# ESP32-C5 register map
Vendor: ESPRESSIF SYSTEMS (SHANGHAI) CO., LTD.; Series: ESP32 C-Series; File version: 1
CPU: RV32IMAC r0p0, little endian, no MPU, no FPU, 0 interrupt priority bits
Address unit: 32 bits
Registers are 32-bit, read-write, reset 0x0 unless marked. A register's access mark holds for its fields unless they carry their own. Offsets are from the block's base; [hi:lo] are bit positions; {n}, {i} and the like mark numbered series.

## SOC_ETM (part 2 of 2) — Event Task Matrix
Base 0x60013000
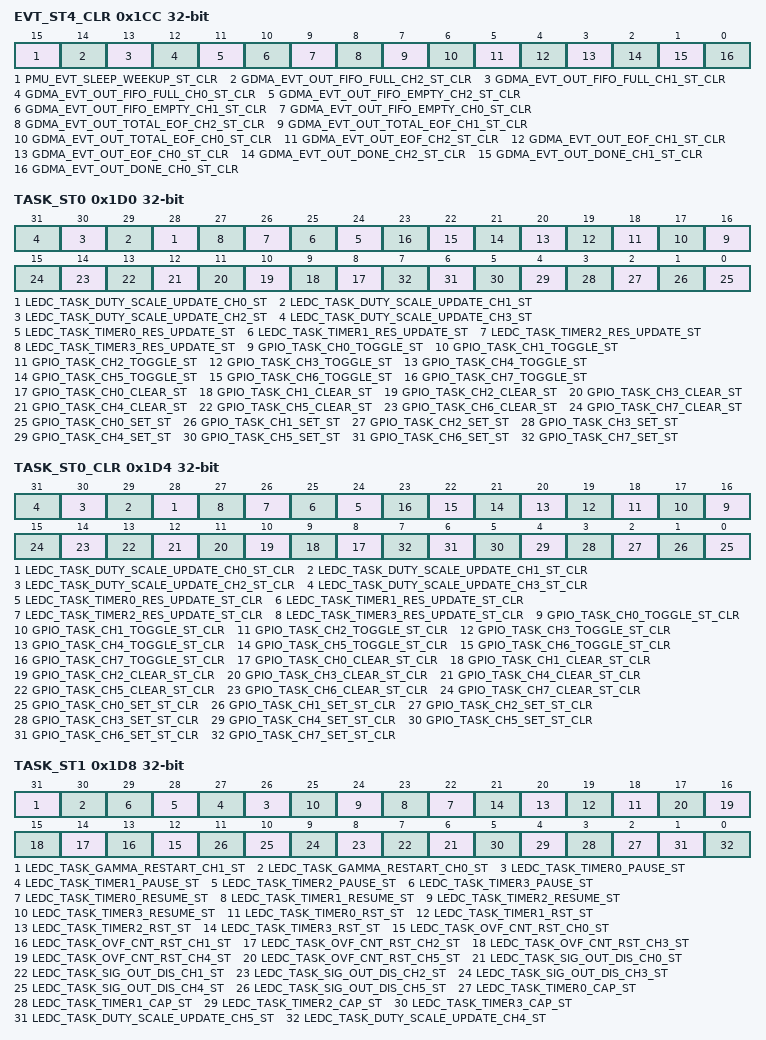
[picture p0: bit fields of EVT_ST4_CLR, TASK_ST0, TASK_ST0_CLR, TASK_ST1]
0x1CC EVT_ST4_CLR wo — Events trigger status clear register
  [15] PMU_EVT_SLEEP_WEEKUP_ST_CLR — Configures whether or not to clear PMU_evt_sleep_weekup trigger status.\\0: Invalid, No effect\\1: Clear
  [14] GDMA_EVT_OUT_FIFO_FULL_CH2_ST_CLR — Configures whether or not to clear GDMA_evt_out_fifo_full_ch2 trigger status.\\0: Invalid, No effect\\1: Clear
  [13] GDMA_EVT_OUT_FIFO_FULL_CH1_ST_CLR — Configures whether or not to clear GDMA_evt_out_fifo_full_ch1 trigger status.\\0: Invalid, No effect\\1: Clear
  [12] GDMA_EVT_OUT_FIFO_FULL_CH0_ST_CLR — Configures whether or not to clear GDMA_evt_out_fifo_full_ch0 trigger status.\\0: Invalid, No effect\\1: Clear
  [11] GDMA_EVT_OUT_FIFO_EMPTY_CH2_ST_CLR — Configures whether or not to clear GDMA_evt_out_fifo_empty_ch2 trigger status.\\0: Invalid, No effect\\1: Clear
  [10] GDMA_EVT_OUT_FIFO_EMPTY_CH1_ST_CLR — Configures whether or not to clear GDMA_evt_out_fifo_empty_ch1 trigger status.\\0: Invalid, No effect\\1: Clear
  [9] GDMA_EVT_OUT_FIFO_EMPTY_CH0_ST_CLR — Configures whether or not to clear GDMA_evt_out_fifo_empty_ch0 trigger status.\\0: Invalid, No effect\\1: Clear
  [8] GDMA_EVT_OUT_TOTAL_EOF_CH2_ST_CLR — Configures whether or not to clear GDMA_evt_out_total_eof_ch2 trigger status.\\0: Invalid, No effect\\1: Clear
  [7] GDMA_EVT_OUT_TOTAL_EOF_CH1_ST_CLR — Configures whether or not to clear GDMA_evt_out_total_eof_ch1 trigger status.\\0: Invalid, No effect\\1: Clear
  [6] GDMA_EVT_OUT_TOTAL_EOF_CH0_ST_CLR — Configures whether or not to clear GDMA_evt_out_total_eof_ch0 trigger status.\\0: Invalid, No effect\\1: Clear
  [5] GDMA_EVT_OUT_EOF_CH2_ST_CLR — Configures whether or not to clear GDMA_evt_out_eof_ch2 trigger status.\\0: Invalid, No effect\\1: Clear
  [4] GDMA_EVT_OUT_EOF_CH1_ST_CLR — Configures whether or not to clear GDMA_evt_out_eof_ch1 trigger status.\\0: Invalid, No effect\\1: Clear
  [3] GDMA_EVT_OUT_EOF_CH0_ST_CLR — Configures whether or not to clear GDMA_evt_out_eof_ch0 trigger status.\\0: Invalid, No effect\\1: Clear
  [2] GDMA_EVT_OUT_DONE_CH2_ST_CLR — Configures whether or not to clear GDMA_evt_out_done_ch2 trigger status.\\0: Invalid, No effect\\1: Clear
  [1] GDMA_EVT_OUT_DONE_CH1_ST_CLR — Configures whether or not to clear GDMA_evt_out_done_ch1 trigger status.\\0: Invalid, No effect\\1: Clear
  [0] GDMA_EVT_OUT_DONE_CH0_ST_CLR — Configures whether or not to clear GDMA_evt_out_done_ch0 trigger status.\\0: Invalid, No effect\\1: Clear
0x1D0 TASK_ST0 — Tasks trigger status register
  [n+28] LEDC_TASK_DUTY_SCALE_UPDATE_CH{n}_ST (n=0..3) — Represents LEDC_task_duty_scale_update_ch{n} trigger status.\\0: Not triggered\\1: Triggered
  [n+24] LEDC_TASK_TIMER{n}_RES_UPDATE_ST (n=0..3) — Represents LEDC_task_timer{n}_res_update trigger status.\\0: Not triggered\\1: Triggered
  [n+16] GPIO_TASK_CH{n}_TOGGLE_ST (n=0..7) — Represents GPIO_task_ch{n}_toggle trigger status.\\0: Not triggered\\1: Triggered
  [n+8] GPIO_TASK_CH{n}_CLEAR_ST (n=0..7) — Represents GPIO_task_ch{n}_clear trigger status.\\0: Not triggered\\1: Triggered
  [n] GPIO_TASK_CH{n}_SET_ST (n=0..7) — Represents GPIO_task_ch{n}_set trigger status.\\0: Not triggered\\1: Triggered
0x1D4 TASK_ST0_CLR wo — Tasks trigger status clear register
  [n+28] LEDC_TASK_DUTY_SCALE_UPDATE_CH{n}_ST_CLR (n=0..3) — Configures whether or not to clear LEDC_task_duty_scale_update_ch{n} trigger status.\\0: Invalid, No effect\\1: Clear
  [n+24] LEDC_TASK_TIMER{n}_RES_UPDATE_ST_CLR (n=0..3) — Configures whether or not to clear LEDC_task_timer{n}_res_update trigger status.\\0: Invalid, No effect\\1: Clear
  [n+16] GPIO_TASK_CH{n}_TOGGLE_ST_CLR (n=0..7) — Configures whether or not to clear GPIO_task_ch{n}_toggle trigger status.\\0: Invalid, No effect\\1: Clear
  [n+8] GPIO_TASK_CH{n}_CLEAR_ST_CLR (n=0..7) — Configures whether or not to clear GPIO_task_ch{n}_clear trigger status.\\0: Invalid, No effect\\1: Clear
  [n] GPIO_TASK_CH{n}_SET_ST_CLR (n=0..7) — Configures whether or not to clear GPIO_task_ch{n}_set trigger status.\\0: Invalid, No effect\\1: Clear
0x1D8 TASK_ST1 — Tasks trigger status register
  [31] LEDC_TASK_GAMMA_RESTART_CH1_ST — Represents LEDC_task_gamma_restart_ch1 trigger status.\\0: Not triggered\\1: Triggered
  [30] LEDC_TASK_GAMMA_RESTART_CH0_ST — Represents LEDC_task_gamma_restart_ch0 trigger status.\\0: Not triggered\\1: Triggered
  [n+26] LEDC_TASK_TIMER{n}_PAUSE_ST (n=0..3) — Represents LEDC_task_timer{n}_pause trigger status.\\0: Not triggered\\1: Triggered
  [n+22] LEDC_TASK_TIMER{n}_RESUME_ST (n=0..3) — Represents LEDC_task_timer{n}_resume trigger status.\\0: Not triggered\\1: Triggered
  [n+18] LEDC_TASK_TIMER{n}_RST_ST (n=0..3) — Represents LEDC_task_timer{n}_rst trigger status.\\0: Not triggered\\1: Triggered
  [n+12] LEDC_TASK_OVF_CNT_RST_CH{n}_ST (n=0..5) — Represents LEDC_task_ovf_cnt_rst_ch{n} trigger status.\\0: Not triggered\\1: Triggered
  [n+6] LEDC_TASK_SIG_OUT_DIS_CH{n}_ST (n=0..5) — Represents LEDC_task_sig_out_dis_ch{n} trigger status.\\0: Not triggered\\1: Triggered
  [n+2] LEDC_TASK_TIMER{n}_CAP_ST (n=0..3) — Represents LEDC_task_timer{n}_cap trigger status.\\0: Not triggered\\1: Triggered
  [1] LEDC_TASK_DUTY_SCALE_UPDATE_CH5_ST — Represents LEDC_task_duty_scale_update_ch5 trigger status.\\0: Not triggered\\1: Triggered
  [0] LEDC_TASK_DUTY_SCALE_UPDATE_CH4_ST — Represents LEDC_task_duty_scale_update_ch4 trigger status.\\0: Not triggered\\1: Triggered
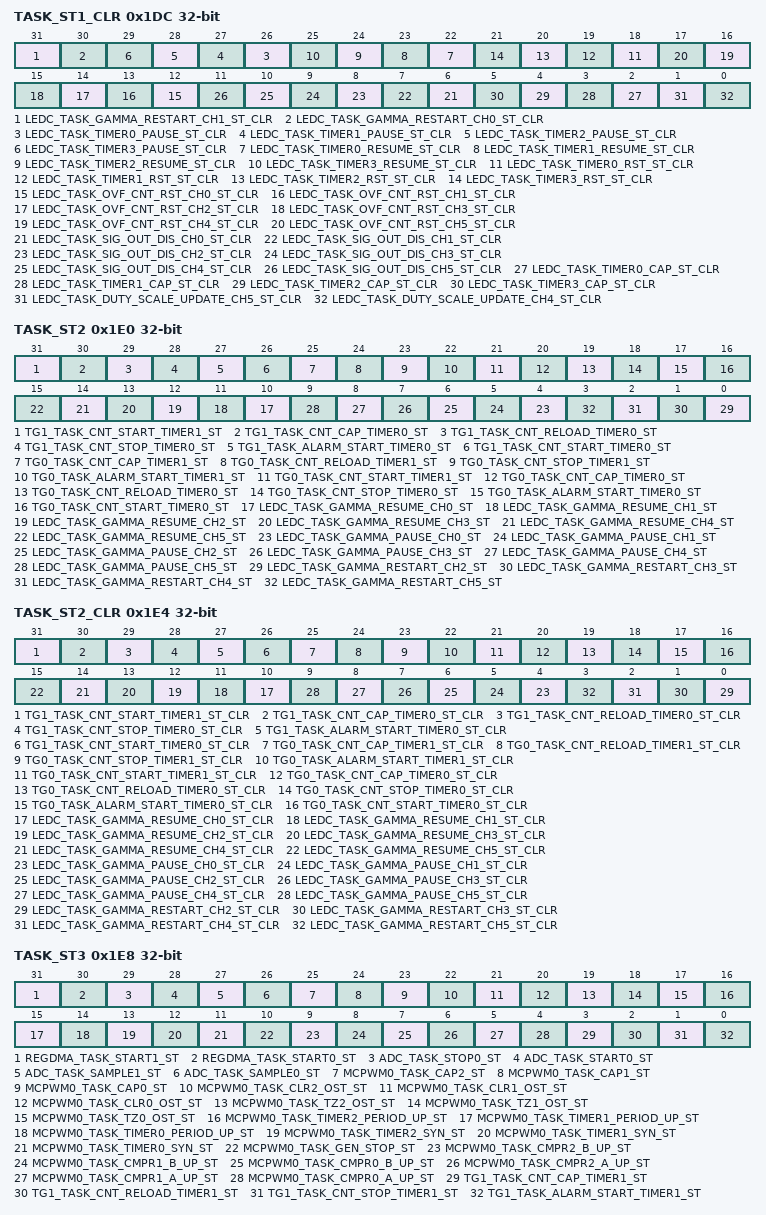
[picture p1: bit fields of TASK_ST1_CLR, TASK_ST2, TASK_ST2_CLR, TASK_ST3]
0x1DC TASK_ST1_CLR wo — Tasks trigger status clear register
  [31] LEDC_TASK_GAMMA_RESTART_CH1_ST_CLR — Configures whether or not to clear LEDC_task_gamma_restart_ch1 trigger status.\\0: Invalid, No effect\\1: Clear
  [30] LEDC_TASK_GAMMA_RESTART_CH0_ST_CLR — Configures whether or not to clear LEDC_task_gamma_restart_ch0 trigger status.\\0: Invalid, No effect\\1: Clear
  [n+26] LEDC_TASK_TIMER{n}_PAUSE_ST_CLR (n=0..3) — Configures whether or not to clear LEDC_task_timer{n}_pause trigger status.\\0: Invalid, No effect\\1: Clear
  [n+22] LEDC_TASK_TIMER{n}_RESUME_ST_CLR (n=0..3) — Configures whether or not to clear LEDC_task_timer{n}_resume trigger status.\\0: Invalid, No effect\\1: Clear
  [n+18] LEDC_TASK_TIMER{n}_RST_ST_CLR (n=0..3) — Configures whether or not to clear LEDC_task_timer{n}_rst trigger status.\\0: Invalid, No effect\\1: Clear
  [n+12] LEDC_TASK_OVF_CNT_RST_CH{n}_ST_CLR (n=0..5) — Configures whether or not to clear LEDC_task_ovf_cnt_rst_ch{n} trigger status.\\0: Invalid, No effect\\1: Clear
  [n+6] LEDC_TASK_SIG_OUT_DIS_CH{n}_ST_CLR (n=0..5) — Configures whether or not to clear LEDC_task_sig_out_dis_ch{n} trigger status.\\0: Invalid, No effect\\1: Clear
  [n+2] LEDC_TASK_TIMER{n}_CAP_ST_CLR (n=0..3) — Configures whether or not to clear LEDC_task_timer{n}_cap trigger status.\\0: Invalid, No effect\\1: Clear
  [1] LEDC_TASK_DUTY_SCALE_UPDATE_CH5_ST_CLR — Configures whether or not to clear LEDC_task_duty_scale_update_ch5 trigger status.\\0: Invalid, No effect\\1: Clear
  [0] LEDC_TASK_DUTY_SCALE_UPDATE_CH4_ST_CLR — Configures whether or not to clear LEDC_task_duty_scale_update_ch4 trigger status.\\0: Invalid, No effect\\1: Clear
0x1E0 TASK_ST2 — Tasks trigger status register
  [31] TG1_TASK_CNT_START_TIMER1_ST — Represents TG1_task_cnt_start_timer1 trigger status.\\0: Not triggered\\1: Triggered
  [30] TG1_TASK_CNT_CAP_TIMER0_ST — Represents TG1_task_cnt_cap_timer0 trigger status.\\0: Not triggered\\1: Triggered
  [29] TG1_TASK_CNT_RELOAD_TIMER0_ST — Represents TG1_task_cnt_reload_timer0 trigger status.\\0: Not triggered\\1: Triggered
  [28] TG1_TASK_CNT_STOP_TIMER0_ST — Represents TG1_task_cnt_stop_timer0 trigger status.\\0: Not triggered\\1: Triggered
  [27] TG1_TASK_ALARM_START_TIMER0_ST — Represents TG1_task_alarm_start_timer0 trigger status.\\0: Not triggered\\1: Triggered
  [26] TG1_TASK_CNT_START_TIMER0_ST — Represents TG1_task_cnt_start_timer0 trigger status.\\0: Not triggered\\1: Triggered
  [25] TG0_TASK_CNT_CAP_TIMER1_ST — Represents TG0_task_cnt_cap_timer1 trigger status.\\0: Not triggered\\1: Triggered
  [24] TG0_TASK_CNT_RELOAD_TIMER1_ST — Represents TG0_task_cnt_reload_timer1 trigger status.\\0: Not triggered\\1: Triggered
  [23] TG0_TASK_CNT_STOP_TIMER1_ST — Represents TG0_task_cnt_stop_timer1 trigger status.\\0: Not triggered\\1: Triggered
  [22] TG0_TASK_ALARM_START_TIMER1_ST — Represents TG0_task_alarm_start_timer1 trigger status.\\0: Not triggered\\1: Triggered
  [21] TG0_TASK_CNT_START_TIMER1_ST — Represents TG0_task_cnt_start_timer1 trigger status.\\0: Not triggered\\1: Triggered
  [20] TG0_TASK_CNT_CAP_TIMER0_ST — Represents TG0_task_cnt_cap_timer0 trigger status.\\0: Not triggered\\1: Triggered
  [19] TG0_TASK_CNT_RELOAD_TIMER0_ST — Represents TG0_task_cnt_reload_timer0 trigger status.\\0: Not triggered\\1: Triggered
  [18] TG0_TASK_CNT_STOP_TIMER0_ST — Represents TG0_task_cnt_stop_timer0 trigger status.\\0: Not triggered\\1: Triggered
  [17] TG0_TASK_ALARM_START_TIMER0_ST — Represents TG0_task_alarm_start_timer0 trigger status.\\0: Not triggered\\1: Triggered
  [16] TG0_TASK_CNT_START_TIMER0_ST — Represents TG0_task_cnt_start_timer0 trigger status.\\0: Not triggered\\1: Triggered
  [n+10] LEDC_TASK_GAMMA_RESUME_CH{n}_ST (n=0..5) — Represents LEDC_task_gamma_resume_ch{n} trigger status.\\0: Not triggered\\1: Triggered
  [n+4] LEDC_TASK_GAMMA_PAUSE_CH{n}_ST (n=0..5) — Represents LEDC_task_gamma_pause_ch{n} trigger status.\\0: Not triggered\\1: Triggered
  [n-2] LEDC_TASK_GAMMA_RESTART_CH{n}_ST (n=2..5) — Represents LEDC_task_gamma_restart_ch{n} trigger status.\\0: Not triggered\\1: Triggered
0x1E4 TASK_ST2_CLR wo — Tasks trigger status clear register
  [31] TG1_TASK_CNT_START_TIMER1_ST_CLR — Configures whether or not to clear TG1_task_cnt_start_timer1 trigger status.\\0: Invalid, No effect\\1: Clear
  [30] TG1_TASK_CNT_CAP_TIMER0_ST_CLR — Configures whether or not to clear TG1_task_cnt_cap_timer0 trigger status.\\0: Invalid, No effect\\1: Clear
  [29] TG1_TASK_CNT_RELOAD_TIMER0_ST_CLR — Configures whether or not to clear TG1_task_cnt_reload_timer0 trigger status.\\0: Invalid, No effect\\1: Clear
  [28] TG1_TASK_CNT_STOP_TIMER0_ST_CLR — Configures whether or not to clear TG1_task_cnt_stop_timer0 trigger status.\\0: Invalid, No effect\\1: Clear
  [27] TG1_TASK_ALARM_START_TIMER0_ST_CLR — Configures whether or not to clear TG1_task_alarm_start_timer0 trigger status.\\0: Invalid, No effect\\1: Clear
  [26] TG1_TASK_CNT_START_TIMER0_ST_CLR — Configures whether or not to clear TG1_task_cnt_start_timer0 trigger status.\\0: Invalid, No effect\\1: Clear
  [25] TG0_TASK_CNT_CAP_TIMER1_ST_CLR — Configures whether or not to clear TG0_task_cnt_cap_timer1 trigger status.\\0: Invalid, No effect\\1: Clear
  [24] TG0_TASK_CNT_RELOAD_TIMER1_ST_CLR — Configures whether or not to clear TG0_task_cnt_reload_timer1 trigger status.\\0: Invalid, No effect\\1: Clear
  [23] TG0_TASK_CNT_STOP_TIMER1_ST_CLR — Configures whether or not to clear TG0_task_cnt_stop_timer1 trigger status.\\0: Invalid, No effect\\1: Clear
  [22] TG0_TASK_ALARM_START_TIMER1_ST_CLR — Configures whether or not to clear TG0_task_alarm_start_timer1 trigger status.\\0: Invalid, No effect\\1: Clear
  [21] TG0_TASK_CNT_START_TIMER1_ST_CLR — Configures whether or not to clear TG0_task_cnt_start_timer1 trigger status.\\0: Invalid, No effect\\1: Clear
  [20] TG0_TASK_CNT_CAP_TIMER0_ST_CLR — Configures whether or not to clear TG0_task_cnt_cap_timer0 trigger status.\\0: Invalid, No effect\\1: Clear
  [19] TG0_TASK_CNT_RELOAD_TIMER0_ST_CLR — Configures whether or not to clear TG0_task_cnt_reload_timer0 trigger status.\\0: Invalid, No effect\\1: Clear
  [18] TG0_TASK_CNT_STOP_TIMER0_ST_CLR — Configures whether or not to clear TG0_task_cnt_stop_timer0 trigger status.\\0: Invalid, No effect\\1: Clear
  [17] TG0_TASK_ALARM_START_TIMER0_ST_CLR — Configures whether or not to clear TG0_task_alarm_start_timer0 trigger status.\\0: Invalid, No effect\\1: Clear
  [16] TG0_TASK_CNT_START_TIMER0_ST_CLR — Configures whether or not to clear TG0_task_cnt_start_timer0 trigger status.\\0: Invalid, No effect\\1: Clear
  [n+10] LEDC_TASK_GAMMA_RESUME_CH{n}_ST_CLR (n=0..5) — Configures whether or not to clear LEDC_task_gamma_resume_ch{n} trigger status.\\0: Invalid, No effect\\1: Clear
  [n+4] LEDC_TASK_GAMMA_PAUSE_CH{n}_ST_CLR (n=0..5) — Configures whether or not to clear LEDC_task_gamma_pause_ch{n} trigger status.\\0: Invalid, No effect\\1: Clear
  [n-2] LEDC_TASK_GAMMA_RESTART_CH{n}_ST_CLR (n=2..5) — Configures whether or not to clear LEDC_task_gamma_restart_ch{n} trigger status.\\0: Invalid, No effect\\1: Clear
0x1E8 TASK_ST3 — Tasks trigger status register
  [31] REGDMA_TASK_START1_ST — Represents REGDMA_task_start1 trigger status.\\0: Not triggered\\1: Triggered
  [30] REGDMA_TASK_START0_ST — Represents REGDMA_task_start0 trigger status.\\0: Not triggered\\1: Triggered
  [29] ADC_TASK_STOP0_ST — Represents ADC_task_stop0 trigger status.\\0: Not triggered\\1: Triggered
  [28] ADC_TASK_START0_ST — Represents ADC_task_start0 trigger status.\\0: Not triggered\\1: Triggered
  [27] ADC_TASK_SAMPLE1_ST — Represents ADC_task_sample1 trigger status.\\0: Not triggered\\1: Triggered
  [26] ADC_TASK_SAMPLE0_ST — Represents ADC_task_sample0 trigger status.\\0: Not triggered\\1: Triggered
  [25] MCPWM0_TASK_CAP2_ST — Represents MCPWM0_task_cap2 trigger status.\\0: Not triggered\\1: Triggered
  [24] MCPWM0_TASK_CAP1_ST — Represents MCPWM0_task_cap1 trigger status.\\0: Not triggered\\1: Triggered
  [23] MCPWM0_TASK_CAP0_ST — Represents MCPWM0_task_cap0 trigger status.\\0: Not triggered\\1: Triggered
  [22] MCPWM0_TASK_CLR2_OST_ST — Represents MCPWM0_task_clr2_ost trigger status.\\0: Not triggered\\1: Triggered
  [21] MCPWM0_TASK_CLR1_OST_ST — Represents MCPWM0_task_clr1_ost trigger status.\\0: Not triggered\\1: Triggered
  [20] MCPWM0_TASK_CLR0_OST_ST — Represents MCPWM0_task_clr0_ost trigger status.\\0: Not triggered\\1: Triggered
  [19] MCPWM0_TASK_TZ2_OST_ST — Represents MCPWM0_task_tz2_ost trigger status.\\0: Not triggered\\1: Triggered
  [18] MCPWM0_TASK_TZ1_OST_ST — Represents MCPWM0_task_tz1_ost trigger status.\\0: Not triggered\\1: Triggered
  [17] MCPWM0_TASK_TZ0_OST_ST — Represents MCPWM0_task_tz0_ost trigger status.\\0: Not triggered\\1: Triggered
  [16] MCPWM0_TASK_TIMER2_PERIOD_UP_ST — Represents MCPWM0_task_timer2_period_up trigger status.\\0: Not triggered\\1: Triggered
  [15] MCPWM0_TASK_TIMER1_PERIOD_UP_ST — Represents MCPWM0_task_timer1_period_up trigger status.\\0: Not triggered\\1: Triggered
  [14] MCPWM0_TASK_TIMER0_PERIOD_UP_ST — Represents MCPWM0_task_timer0_period_up trigger status.\\0: Not triggered\\1: Triggered
  [13] MCPWM0_TASK_TIMER2_SYN_ST — Represents MCPWM0_task_timer2_syn trigger status.\\0: Not triggered\\1: Triggered
  [12] MCPWM0_TASK_TIMER1_SYN_ST — Represents MCPWM0_task_timer1_syn trigger status.\\0: Not triggered\\1: Triggered
  [11] MCPWM0_TASK_TIMER0_SYN_ST — Represents MCPWM0_task_timer0_syn trigger status.\\0: Not triggered\\1: Triggered
  [10] MCPWM0_TASK_GEN_STOP_ST — Represents MCPWM0_task_gen_stop trigger status.\\0: Not triggered\\1: Triggered
  [9] MCPWM0_TASK_CMPR2_B_UP_ST — Represents MCPWM0_task_cmpr2_b_up trigger status.\\0: Not triggered\\1: Triggered
  [8] MCPWM0_TASK_CMPR1_B_UP_ST — Represents MCPWM0_task_cmpr1_b_up trigger status.\\0: Not triggered\\1: Triggered
  [7] MCPWM0_TASK_CMPR0_B_UP_ST — Represents MCPWM0_task_cmpr0_b_up trigger status.\\0: Not triggered\\1: Triggered
  [6] MCPWM0_TASK_CMPR2_A_UP_ST — Represents MCPWM0_task_cmpr2_a_up trigger status.\\0: Not triggered\\1: Triggered
  [5] MCPWM0_TASK_CMPR1_A_UP_ST — Represents MCPWM0_task_cmpr1_a_up trigger status.\\0: Not triggered\\1: Triggered
  [4] MCPWM0_TASK_CMPR0_A_UP_ST — Represents MCPWM0_task_cmpr0_a_up trigger status.\\0: Not triggered\\1: Triggered
  [3] TG1_TASK_CNT_CAP_TIMER1_ST — Represents TG1_task_cnt_cap_timer1 trigger status.\\0: Not triggered\\1: Triggered
  [2] TG1_TASK_CNT_RELOAD_TIMER1_ST — Represents TG1_task_cnt_reload_timer1 trigger status.\\0: Not triggered\\1: Triggered
  [1] TG1_TASK_CNT_STOP_TIMER1_ST — Represents TG1_task_cnt_stop_timer1 trigger status.\\0: Not triggered\\1: Triggered
  [0] TG1_TASK_ALARM_START_TIMER1_ST — Represents TG1_task_alarm_start_timer1 trigger status.\\0: Not triggered\\1: Triggered
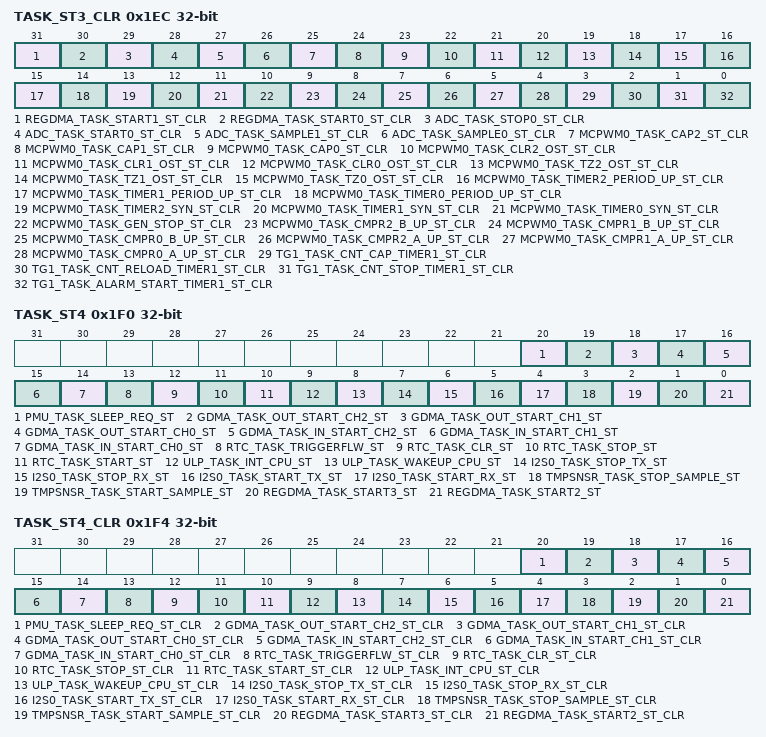
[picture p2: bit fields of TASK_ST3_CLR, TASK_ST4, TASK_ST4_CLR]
0x1EC TASK_ST3_CLR wo — Tasks trigger status clear register
  [31] REGDMA_TASK_START1_ST_CLR — Configures whether or not to clear REGDMA_task_start1 trigger status.\\0: Invalid, No effect\\1: Clear
  [30] REGDMA_TASK_START0_ST_CLR — Configures whether or not to clear REGDMA_task_start0 trigger status.\\0: Invalid, No effect\\1: Clear
  [29] ADC_TASK_STOP0_ST_CLR — Configures whether or not to clear ADC_task_stop0 trigger status.\\0: Invalid, No effect\\1: Clear
  [28] ADC_TASK_START0_ST_CLR — Configures whether or not to clear ADC_task_start0 trigger status.\\0: Invalid, No effect\\1: Clear
  [27] ADC_TASK_SAMPLE1_ST_CLR — Configures whether or not to clear ADC_task_sample1 trigger status.\\0: Invalid, No effect\\1: Clear
  [26] ADC_TASK_SAMPLE0_ST_CLR — Configures whether or not to clear ADC_task_sample0 trigger status.\\0: Invalid, No effect\\1: Clear
  [25] MCPWM0_TASK_CAP2_ST_CLR — Configures whether or not to clear MCPWM0_task_cap2 trigger status.\\0: Invalid, No effect\\1: Clear
  [24] MCPWM0_TASK_CAP1_ST_CLR — Configures whether or not to clear MCPWM0_task_cap1 trigger status.\\0: Invalid, No effect\\1: Clear
  [23] MCPWM0_TASK_CAP0_ST_CLR — Configures whether or not to clear MCPWM0_task_cap0 trigger status.\\0: Invalid, No effect\\1: Clear
  [22] MCPWM0_TASK_CLR2_OST_ST_CLR — Configures whether or not to clear MCPWM0_task_clr2_ost trigger status.\\0: Invalid, No effect\\1: Clear
  [21] MCPWM0_TASK_CLR1_OST_ST_CLR — Configures whether or not to clear MCPWM0_task_clr1_ost trigger status.\\0: Invalid, No effect\\1: Clear
  [20] MCPWM0_TASK_CLR0_OST_ST_CLR — Configures whether or not to clear MCPWM0_task_clr0_ost trigger status.\\0: Invalid, No effect\\1: Clear
  [19] MCPWM0_TASK_TZ2_OST_ST_CLR — Configures whether or not to clear MCPWM0_task_tz2_ost trigger status.\\0: Invalid, No effect\\1: Clear
  [18] MCPWM0_TASK_TZ1_OST_ST_CLR — Configures whether or not to clear MCPWM0_task_tz1_ost trigger status.\\0: Invalid, No effect\\1: Clear
  [17] MCPWM0_TASK_TZ0_OST_ST_CLR — Configures whether or not to clear MCPWM0_task_tz0_ost trigger status.\\0: Invalid, No effect\\1: Clear
  [16] MCPWM0_TASK_TIMER2_PERIOD_UP_ST_CLR — Configures whether or not to clear MCPWM0_task_timer2_period_up trigger status.\\0: Invalid, No effect\\1: Clear
  [15] MCPWM0_TASK_TIMER1_PERIOD_UP_ST_CLR — Configures whether or not to clear MCPWM0_task_timer1_period_up trigger status.\\0: Invalid, No effect\\1: Clear
  [14] MCPWM0_TASK_TIMER0_PERIOD_UP_ST_CLR — Configures whether or not to clear MCPWM0_task_timer0_period_up trigger status.\\0: Invalid, No effect\\1: Clear
  [13] MCPWM0_TASK_TIMER2_SYN_ST_CLR — Configures whether or not to clear MCPWM0_task_timer2_syn trigger status.\\0: Invalid, No effect\\1: Clear
  [12] MCPWM0_TASK_TIMER1_SYN_ST_CLR — Configures whether or not to clear MCPWM0_task_timer1_syn trigger status.\\0: Invalid, No effect\\1: Clear
  [11] MCPWM0_TASK_TIMER0_SYN_ST_CLR — Configures whether or not to clear MCPWM0_task_timer0_syn trigger status.\\0: Invalid, No effect\\1: Clear
  [10] MCPWM0_TASK_GEN_STOP_ST_CLR — Configures whether or not to clear MCPWM0_task_gen_stop trigger status.\\0: Invalid, No effect\\1: Clear
  [9] MCPWM0_TASK_CMPR2_B_UP_ST_CLR — Configures whether or not to clear MCPWM0_task_cmpr2_b_up trigger status.\\0: Invalid, No effect\\1: Clear
  [8] MCPWM0_TASK_CMPR1_B_UP_ST_CLR — Configures whether or not to clear MCPWM0_task_cmpr1_b_up trigger status.\\0: Invalid, No effect\\1: Clear
  [7] MCPWM0_TASK_CMPR0_B_UP_ST_CLR — Configures whether or not to clear MCPWM0_task_cmpr0_b_up trigger status.\\0: Invalid, No effect\\1: Clear
  [6] MCPWM0_TASK_CMPR2_A_UP_ST_CLR — Configures whether or not to clear MCPWM0_task_cmpr2_a_up trigger status.\\0: Invalid, No effect\\1: Clear
  [5] MCPWM0_TASK_CMPR1_A_UP_ST_CLR — Configures whether or not to clear MCPWM0_task_cmpr1_a_up trigger status.\\0: Invalid, No effect\\1: Clear
  [4] MCPWM0_TASK_CMPR0_A_UP_ST_CLR — Configures whether or not to clear MCPWM0_task_cmpr0_a_up trigger status.\\0: Invalid, No effect\\1: Clear
  [3] TG1_TASK_CNT_CAP_TIMER1_ST_CLR — Configures whether or not to clear TG1_task_cnt_cap_timer1 trigger status.\\0: Invalid, No effect\\1: Clear
  [2] TG1_TASK_CNT_RELOAD_TIMER1_ST_CLR — Configures whether or not to clear TG1_task_cnt_reload_timer1 trigger status.\\0: Invalid, No effect\\1: Clear
  [1] TG1_TASK_CNT_STOP_TIMER1_ST_CLR — Configures whether or not to clear TG1_task_cnt_stop_timer1 trigger status.\\0: Invalid, No effect\\1: Clear
  [0] TG1_TASK_ALARM_START_TIMER1_ST_CLR — Configures whether or not to clear TG1_task_alarm_start_timer1 trigger status.\\0: Invalid, No effect\\1: Clear
0x1F0 TASK_ST4 — Tasks trigger status register
  [20] PMU_TASK_SLEEP_REQ_ST — Represents PMU_task_sleep_req trigger status.\\0: Not triggered\\1: Triggered
  [19] GDMA_TASK_OUT_START_CH2_ST — Represents GDMA_task_out_start_ch2 trigger status.\\0: Not triggered\\1: Triggered
  [18] GDMA_TASK_OUT_START_CH1_ST — Represents GDMA_task_out_start_ch1 trigger status.\\0: Not triggered\\1: Triggered
  [17] GDMA_TASK_OUT_START_CH0_ST — Represents GDMA_task_out_start_ch0 trigger status.\\0: Not triggered\\1: Triggered
  [16] GDMA_TASK_IN_START_CH2_ST — Represents GDMA_task_in_start_ch2 trigger status.\\0: Not triggered\\1: Triggered
  [15] GDMA_TASK_IN_START_CH1_ST — Represents GDMA_task_in_start_ch1 trigger status.\\0: Not triggered\\1: Triggered
  [14] GDMA_TASK_IN_START_CH0_ST — Represents GDMA_task_in_start_ch0 trigger status.\\0: Not triggered\\1: Triggered
  [13] RTC_TASK_TRIGGERFLW_ST — Represents RTC_task_triggerflw trigger status.\\0: Not triggered\\1: Triggered
  [12] RTC_TASK_CLR_ST — Represents RTC_task_clr trigger status.\\0: Not triggered\\1: Triggered
  [11] RTC_TASK_STOP_ST — Represents RTC_task_stop trigger status.\\0: Not triggered\\1: Triggered
  [10] RTC_TASK_START_ST — Represents RTC_task_start trigger status.\\0: Not triggered\\1: Triggered
  [9] ULP_TASK_INT_CPU_ST — Represents ULP_task_int_cpu trigger status.\\0: Not triggered\\1: Triggered
  [8] ULP_TASK_WAKEUP_CPU_ST — Represents ULP_task_wakeup_cpu trigger status.\\0: Not triggered\\1: Triggered
  [7] I2S0_TASK_STOP_TX_ST — Represents I2S0_task_stop_tx trigger status.\\0: Not triggered\\1: Triggered
  [6] I2S0_TASK_STOP_RX_ST — Represents I2S0_task_stop_rx trigger status.\\0: Not triggered\\1: Triggered
  [5] I2S0_TASK_START_TX_ST — Represents I2S0_task_start_tx trigger status.\\0: Not triggered\\1: Triggered
  [4] I2S0_TASK_START_RX_ST — Represents I2S0_task_start_rx trigger status.\\0: Not triggered\\1: Triggered
  [3] TMPSNSR_TASK_STOP_SAMPLE_ST — Represents TMPSNSR_task_stop_sample trigger status.\\0: Not triggered\\1: Triggered
  [2] TMPSNSR_TASK_START_SAMPLE_ST — Represents TMPSNSR_task_start_sample trigger status.\\0: Not triggered\\1: Triggered
  [1] REGDMA_TASK_START3_ST — Represents REGDMA_task_start3 trigger status.\\0: Not triggered\\1: Triggered
  [0] REGDMA_TASK_START2_ST — Represents REGDMA_task_start2 trigger status.\\0: Not triggered\\1: Triggered
0x1F4 TASK_ST4_CLR wo — Tasks trigger status clear register
  [20] PMU_TASK_SLEEP_REQ_ST_CLR — Configures whether or not to clear PMU_task_sleep_req trigger status.\\0: Invalid, No effect\\1: Clear
  [19] GDMA_TASK_OUT_START_CH2_ST_CLR — Configures whether or not to clear GDMA_task_out_start_ch2 trigger status.\\0: Invalid, No effect\\1: Clear
  [18] GDMA_TASK_OUT_START_CH1_ST_CLR — Configures whether or not to clear GDMA_task_out_start_ch1 trigger status.\\0: Invalid, No effect\\1: Clear
  [17] GDMA_TASK_OUT_START_CH0_ST_CLR — Configures whether or not to clear GDMA_task_out_start_ch0 trigger status.\\0: Invalid, No effect\\1: Clear
  [16] GDMA_TASK_IN_START_CH2_ST_CLR — Configures whether or not to clear GDMA_task_in_start_ch2 trigger status.\\0: Invalid, No effect\\1: Clear
  [15] GDMA_TASK_IN_START_CH1_ST_CLR — Configures whether or not to clear GDMA_task_in_start_ch1 trigger status.\\0: Invalid, No effect\\1: Clear
  [14] GDMA_TASK_IN_START_CH0_ST_CLR — Configures whether or not to clear GDMA_task_in_start_ch0 trigger status.\\0: Invalid, No effect\\1: Clear
  [13] RTC_TASK_TRIGGERFLW_ST_CLR — Configures whether or not to clear RTC_task_triggerflw trigger status.\\0: Invalid, No effect\\1: Clear
  [12] RTC_TASK_CLR_ST_CLR — Configures whether or not to clear RTC_task_clr trigger status.\\0: Invalid, No effect\\1: Clear
  [11] RTC_TASK_STOP_ST_CLR — Configures whether or not to clear RTC_task_stop trigger status.\\0: Invalid, No effect\\1: Clear
  [10] RTC_TASK_START_ST_CLR — Configures whether or not to clear RTC_task_start trigger status.\\0: Invalid, No effect\\1: Clear
  [9] ULP_TASK_INT_CPU_ST_CLR — Configures whether or not to clear ULP_task_int_cpu trigger status.\\0: Invalid, No effect\\1: Clear
  [8] ULP_TASK_WAKEUP_CPU_ST_CLR — Configures whether or not to clear ULP_task_wakeup_cpu trigger status.\\0: Invalid, No effect\\1: Clear
  [7] I2S0_TASK_STOP_TX_ST_CLR — Configures whether or not to clear I2S0_task_stop_tx trigger status.\\0: Invalid, No effect\\1: Clear
  [6] I2S0_TASK_STOP_RX_ST_CLR — Configures whether or not to clear I2S0_task_stop_rx trigger status.\\0: Invalid, No effect\\1: Clear
  [5] I2S0_TASK_START_TX_ST_CLR — Configures whether or not to clear I2S0_task_start_tx trigger status.\\0: Invalid, No effect\\1: Clear
  [4] I2S0_TASK_START_RX_ST_CLR — Configures whether or not to clear I2S0_task_start_rx trigger status.\\0: Invalid, No effect\\1: Clear
  [3] TMPSNSR_TASK_STOP_SAMPLE_ST_CLR — Configures whether or not to clear TMPSNSR_task_stop_sample trigger status.\\0: Invalid, No effect\\1: Clear
  [2] TMPSNSR_TASK_START_SAMPLE_ST_CLR — Configures whether or not to clear TMPSNSR_task_start_sample trigger status.\\0: Invalid, No effect\\1: Clear
  [1] REGDMA_TASK_START3_ST_CLR — Configures whether or not to clear REGDMA_task_start3 trigger status.\\0: Invalid, No effect\\1: Clear
  [0] REGDMA_TASK_START2_ST_CLR — Configures whether or not to clear REGDMA_task_start2 trigger status.\\0: Invalid, No effect\\1: Clear
0x1F8 CLK_EN — ETM clock enable register
  [0] CLK_EN — Configures whether or not to open register clock gate.\\0: Open the clock gate only when application writes registers\\1: Force open the clock gate for register
0x1FC DATE reset 0x2311281 — ETM date register
  [27:0] DATE — Configures the version.
